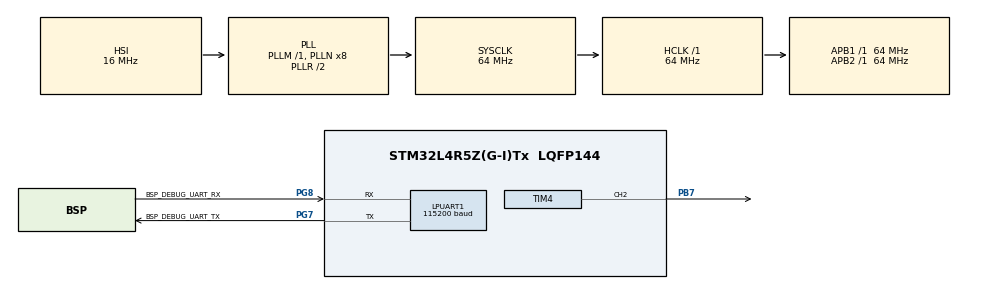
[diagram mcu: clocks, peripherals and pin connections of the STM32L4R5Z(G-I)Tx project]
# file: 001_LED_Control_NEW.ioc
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LPUART1.BaudRate=115200
LPUART1.WordLength=UART_WORDLENGTH_8B
Mcu.Family=STM32L4
Mcu.Name=STM32L4R5Z(G-I)Tx
Mcu.Package=LQFP144
NVIC.PriorityGroup=NVIC_PRIORITYGROUP_4
PB7.Signal=S_TIM4_CH2
PG7.GPIO_Label=BSP_DEBUG_UART_TX
PG7.Mode=Asynchronous
PG7.Signal=LPUART1_TX
PG8.GPIO_Label=BSP_DEBUG_UART_RX
PG8.Mode=Asynchronous
PG8.Signal=LPUART1_RX
ProjectManager.HeapSize=0x200
ProjectManager.StackSize=0x400
ProjectManager.TargetToolchain=STM32CubeIDE
RCC.48MHZClocksFreq_Value=24000000
RCC.ADCFreq_Value=64000000
RCC.AHBFreq_Value=64000000
RCC.APB1Freq_Value=64000000
RCC.APB1TimFreq_Value=64000000
RCC.APB2Freq_Value=64000000
RCC.APB2TimFreq_Value=64000000
RCC.CortexFreq_Value=64000000
RCC.HCLKFreq_Value=64000000
RCC.HSE_VALUE=8000000
RCC.HSI48_VALUE=48000000
RCC.HSI_VALUE=16000000
RCC.MSI_VALUE=4000000
RCC.PLLMUL=RCC_PLL_MUL9
RCC.PLLSourceVirtual=RCC_PLLSOURCE_HSI
RCC.PRESCALERUSB=RCC_USBCLKSOURCE_PLL_DIV1_5
RCC.SYSCLKFreq_VALUE=64000000
RCC.SYSCLKSource=RCC_SYSCLKSOURCE_PLLCLK
RCC.SYSCLKSourceVirtual=RCC_SYSCLKSOURCE_PLLCLK
RCC.USBFreq_Value=64000000
RCC.VCOOutputFreq_Value=128000000
SH.S_TIM4_CH2.0=TIM4_CH2,PWM Generation2 CH2
TIM4.Channel-PWM\ Generation2\ CH2=TIM_CHANNEL_2
TIM4.Period=100-1
TIM4.Prescaler=64-1
VP_TIM4_VS_ClockSourceINT.Mode=Internal
board=NUCLEO-L4R5ZI

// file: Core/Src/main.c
/* USER CODE BEGIN Header */
/**
  ******************************************************************************
  * @file           : main.c
  * @brief          : Main program body
  ******************************************************************************
  * @attention
  *
  * Copyright (c) 2024 STMicroelectronics.
  * All rights reserved.
  *
  * This software is licensed under terms that can be found in the LICENSE file
  * in the root directory of this software component.
  * If no LICENSE file comes with this software, it is provided AS-IS.
  *
  ******************************************************************************
  */
/* USER CODE END Header */
#include "main.h"

/* USER CODE BEGIN Includes */
#include "stdio.h"
/* USER CODE END Includes */

/* USER CODE BEGIN PM */
#define LIGHT_BRIGHT_DIM 25
#define LIGHT_BRIGHT_MED 50
#define LIGHT_BRIGHT_FULL 100
#define LIGHT_BRIGHT_OFF 0
/* USER CODE END PM */

UART_HandleTypeDef hlpuart1;

TIM_HandleTypeDef htim4;

/* USER CODE BEGIN PV */
enum event{
	ON,
	OFF
};

typedef enum {
	LIGHT_OFF,
	LIGHT_DIM,
	LIGHT_MEDIUM,
	LIGHT_FULL
}light_state_t;

light_state_t curr_state = LIGHT_OFF;

uint8_t rx_buffer;
/* USER CODE END PV */

void SystemClock_Config(void);
static void MX_GPIO_Init(void);
static void MX_LPUART1_UART_Init(void);
static void MX_TIM4_Init(void);
/* USER CODE BEGIN PFP */
void light_state_machine(uint8_t event);
void light_change_intensity(uint8_t Intensity);
/* USER CODE END PFP */

/* USER CODE BEGIN 0 */

/* function to control the state machine
 * param : event occured
 * based on the event, current state will change */
void light_state_machine(uint8_t event)
{
	switch (curr_state) {
		case LIGHT_OFF:{
			switch (event) {
				case ON:{
					light_change_intensity(LIGHT_BRIGHT_DIM);
					curr_state = LIGHT_DIM;
					break;
				}
			}
			break;
		}
		case LIGHT_DIM:{
			switch (event) {
				case ON:{
					light_change_intensity(LIGHT_BRIGHT_MED);
					curr_state = LIGHT_MEDIUM;
					break;
				}
				case OFF:{
					light_change_intensity(LIGHT_BRIGHT_OFF);
					curr_state = LIGHT_OFF;
					break;
				}
			}
			break;
		}
		case LIGHT_MEDIUM:{
			switch (event) {
				case ON:{
					light_change_intensity(LIGHT_BRIGHT_FULL);
					curr_state = LIGHT_FULL;
					break;
				}
				case OFF:{
					light_change_intensity(LIGHT_BRIGHT_OFF);
					curr_state = LIGHT_OFF;
					break;
				}
			}
			break;
		}
		case LIGHT_FULL:{
			switch (event) {
				case ON:{
					light_change_intensity(LIGHT_BRIGHT_DIM);
					curr_state = LIGHT_DIM;
					break;
				}
				case OFF:{
					light_change_intensity(LIGHT_BRIGHT_OFF);
					curr_state = LIGHT_OFF;
					break;
				}
			}
			break;
		}
	}
}

/* function to change the intensity of the led
 * param : value to the CCR register (duty cycle) */
void light_change_intensity(uint8_t Intensity)
{
	/* pwm generation function */
	__HAL_TIM_SET_COMPARE(&htim4,TIM_CHANNEL_2,Intensity);
}
/* USER CODE END 0 */

int main(void)
{

  /* MCU Configuration--------------------------------------------------------*/

  /* Reset of all peripherals, Initializes the Flash interface and the Systick. */
  HAL_Init();

  /* Configure the system clock */
  SystemClock_Config();

  /* Initialize all configured peripherals */
  MX_GPIO_Init();
  MX_LPUART1_UART_Init();
  MX_TIM4_Init();
  /* USER CODE BEGIN 2 */

  HAL_TIM_PWM_Start(&htim4, TIM_CHANNEL_2);

  printf("LED Control Application\r\n");
  printf("------------------------------------\r\n");
  printf("Send 'x' or 'o' \r\n");

  /* USER CODE END 2 */

  /* Infinite loop */
  while (1)
  {

    /* USER CODE BEGIN 3 */

	  /* receive the character via UART
	   * based on received command call the funtion to generate respective event */
	  if(HAL_UART_Receive(&hlpuart1, &rx_buffer, 1, HAL_MAX_DELAY)== HAL_OK)
	  {
		  if(rx_buffer == 'o')
		  {
			  light_state_machine(ON);
		  }
		  else if(rx_buffer == 'x')
		  {
			  light_state_machine(OFF);
		  }
	  }
  }
  /* USER CODE END 3 */
}

void SystemClock_Config(void)
{
  RCC_OscInitTypeDef RCC_OscInitStruct = {0};
  RCC_ClkInitTypeDef RCC_ClkInitStruct = {0};

  /** Configure the main internal regulator output voltage
  */
  if (HAL_PWREx_ControlVoltageScaling(PWR_REGULATOR_VOLTAGE_SCALE1) != HAL_OK)
  {
    Error_Handler();
  }

  /** Initializes the RCC Oscillators according to the specified parameters
  * in the RCC_OscInitTypeDef structure.
  */
  RCC_OscInitStruct.OscillatorType = RCC_OSCILLATORTYPE_HSI;
  RCC_OscInitStruct.HSIState = RCC_HSI_ON;
  RCC_OscInitStruct.HSICalibrationValue = RCC_HSICALIBRATION_DEFAULT;
  RCC_OscInitStruct.PLL.PLLState = RCC_PLL_ON;
  RCC_OscInitStruct.PLL.PLLSource = RCC_PLLSOURCE_HSI;
  RCC_OscInitStruct.PLL.PLLM = 1;
  RCC_OscInitStruct.PLL.PLLN = 8;
  RCC_OscInitStruct.PLL.PLLP = RCC_PLLP_DIV2;
  RCC_OscInitStruct.PLL.PLLQ = RCC_PLLQ_DIV2;
  RCC_OscInitStruct.PLL.PLLR = RCC_PLLR_DIV2;
  if (HAL_RCC_OscConfig(&RCC_OscInitStruct) != HAL_OK)
  {
    Error_Handler();
  }

  /** Initializes the CPU, AHB and APB buses clocks
  */
  RCC_ClkInitStruct.ClockType = RCC_CLOCKTYPE_HCLK|RCC_CLOCKTYPE_SYSCLK
                              |RCC_CLOCKTYPE_PCLK1|RCC_CLOCKTYPE_PCLK2;
  RCC_ClkInitStruct.SYSCLKSource = RCC_SYSCLKSOURCE_PLLCLK;
  RCC_ClkInitStruct.AHBCLKDivider = RCC_SYSCLK_DIV1;
  RCC_ClkInitStruct.APB1CLKDivider = RCC_HCLK_DIV1;
  RCC_ClkInitStruct.APB2CLKDivider = RCC_HCLK_DIV1;

  if (HAL_RCC_ClockConfig(&RCC_ClkInitStruct, FLASH_LATENCY_3) != HAL_OK)
  {
    Error_Handler();
  }
}

static void MX_LPUART1_UART_Init(void)
{

  hlpuart1.Instance = LPUART1;
  hlpuart1.Init.BaudRate = 115200;
  hlpuart1.Init.WordLength = UART_WORDLENGTH_8B;
  hlpuart1.Init.StopBits = UART_STOPBITS_1;
  hlpuart1.Init.Parity = UART_PARITY_NONE;
  hlpuart1.Init.Mode = UART_MODE_TX_RX;
  hlpuart1.Init.HwFlowCtl = UART_HWCONTROL_NONE;
  hlpuart1.Init.OneBitSampling = UART_ONE_BIT_SAMPLE_DISABLE;
  hlpuart1.Init.ClockPrescaler = UART_PRESCALER_DIV1;
  hlpuart1.AdvancedInit.AdvFeatureInit = UART_ADVFEATURE_NO_INIT;
  hlpuart1.FifoMode = UART_FIFOMODE_DISABLE;
  if (HAL_UART_Init(&hlpuart1) != HAL_OK)
  {
    Error_Handler();
  }
  if (HAL_UARTEx_SetTxFifoThreshold(&hlpuart1, UART_TXFIFO_THRESHOLD_1_8) != HAL_OK)
  {
    Error_Handler();
  }
  if (HAL_UARTEx_SetRxFifoThreshold(&hlpuart1, UART_RXFIFO_THRESHOLD_1_8) != HAL_OK)
  {
    Error_Handler();
  }
  if (HAL_UARTEx_DisableFifoMode(&hlpuart1) != HAL_OK)
  {
    Error_Handler();
  }

}

static void MX_TIM4_Init(void)
{

  TIM_ClockConfigTypeDef sClockSourceConfig = {0};
  TIM_MasterConfigTypeDef sMasterConfig = {0};
  TIM_OC_InitTypeDef sConfigOC = {0};

  htim4.Instance = TIM4;
  htim4.Init.Prescaler = 64-1;
  htim4.Init.CounterMode = TIM_COUNTERMODE_UP;
  htim4.Init.Period = 100-1;
  htim4.Init.ClockDivision = TIM_CLOCKDIVISION_DIV1;
  htim4.Init.AutoReloadPreload = TIM_AUTORELOAD_PRELOAD_DISABLE;
  if (HAL_TIM_Base_Init(&htim4) != HAL_OK)
  {
    Error_Handler();
  }
  sClockSourceConfig.ClockSource = TIM_CLOCKSOURCE_INTERNAL;
  if (HAL_TIM_ConfigClockSource(&htim4, &sClockSourceConfig) != HAL_OK)
  {
    Error_Handler();
  }
  if (HAL_TIM_PWM_Init(&htim4) != HAL_OK)
  {
    Error_Handler();
  }
  sMasterConfig.MasterOutputTrigger = TIM_TRGO_RESET;
  sMasterConfig.MasterSlaveMode = TIM_MASTERSLAVEMODE_DISABLE;
  if (HAL_TIMEx_MasterConfigSynchronization(&htim4, &sMasterConfig) != HAL_OK)
  {
    Error_Handler();
  }
  sConfigOC.OCMode = TIM_OCMODE_PWM1;
  sConfigOC.Pulse = 0;
  sConfigOC.OCPolarity = TIM_OCPOLARITY_HIGH;
  sConfigOC.OCFastMode = TIM_OCFAST_DISABLE;
  if (HAL_TIM_PWM_ConfigChannel(&htim4, &sConfigOC, TIM_CHANNEL_2) != HAL_OK)
  {
    Error_Handler();
  }
  HAL_TIM_MspPostInit(&htim4);

}

static void MX_GPIO_Init(void)
{

  /* GPIO Ports Clock Enable */
  __HAL_RCC_GPIOG_CLK_ENABLE();
  HAL_PWREx_EnableVddIO2();
  __HAL_RCC_GPIOB_CLK_ENABLE();

}

void Error_Handler(void)
{
  __disable_irq();
  while (1)
  {
  }
}
